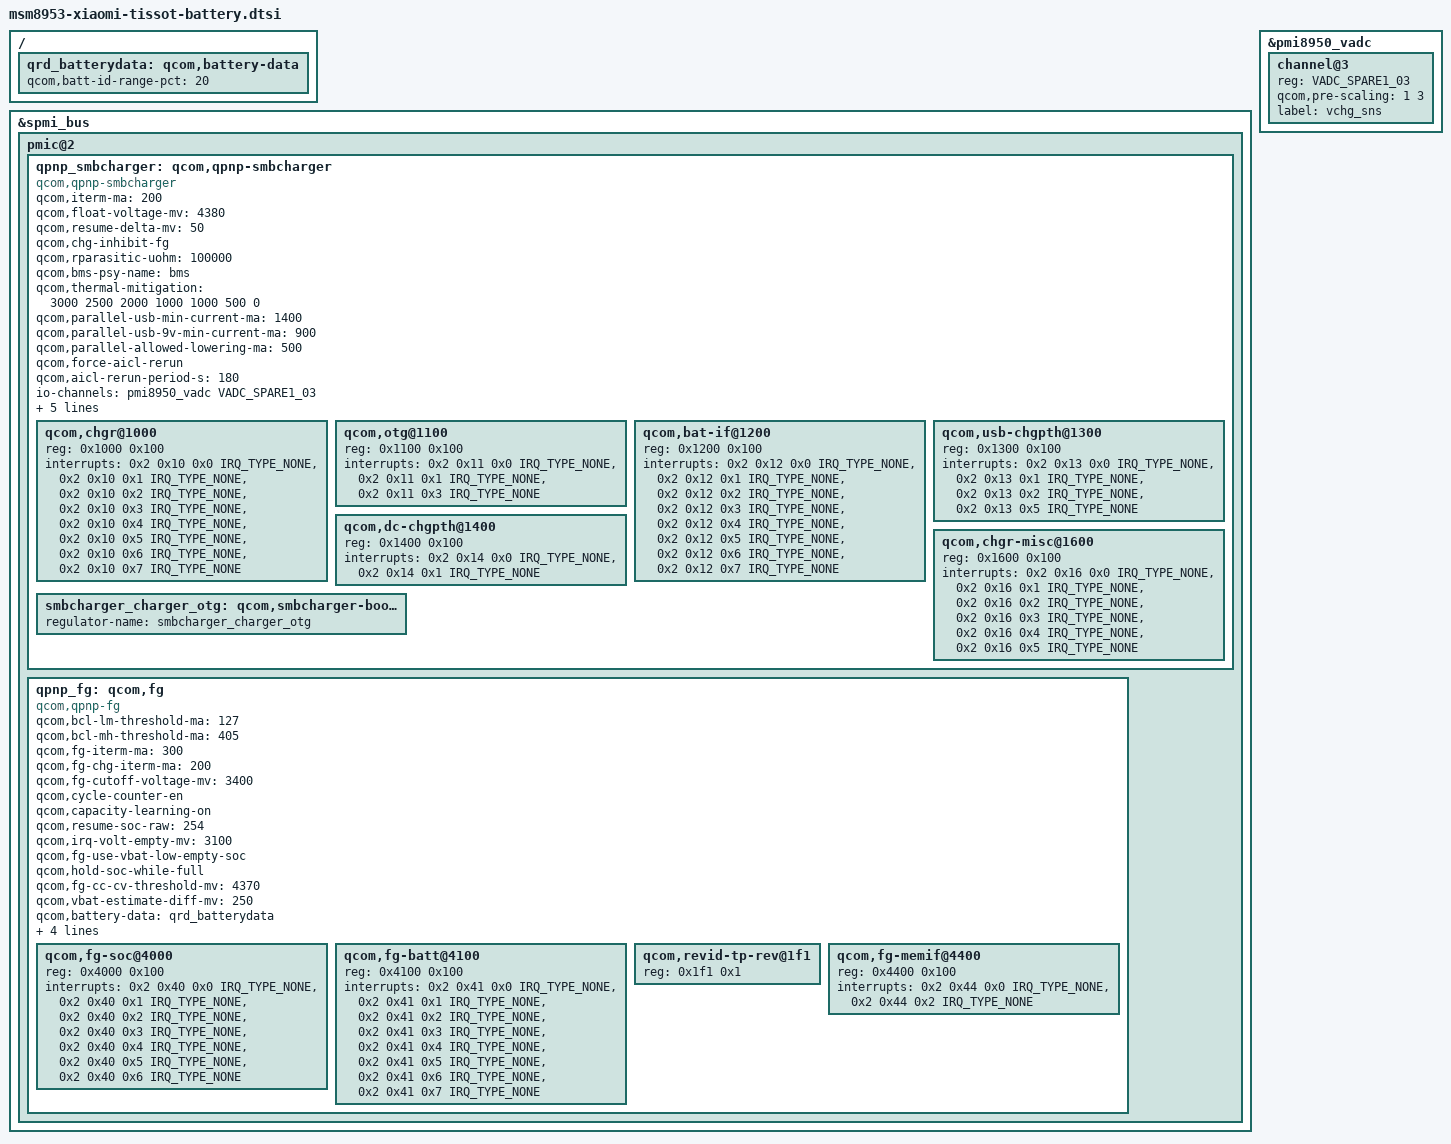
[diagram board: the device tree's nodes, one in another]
// SPDX-License-Identifier: GPL-2.0-only
/* PMI8950 peripheral layout and calibration from the oc-test Tissot donor. */

&spmi_bus {
	pmic@2 {
		qpnp_smbcharger: qcom,qpnp-smbcharger {
			compatible = "qcom,qpnp-smbcharger";
			#address-cells = <1>;
			#size-cells = <1>;
			#cooling-cells = <2>;

			qcom,iterm-ma = <100>;
			qcom,float-voltage-mv = <4200>;
			qcom,resume-delta-mv = <200>;
			qcom,chg-inhibit-fg;
			qcom,rparasitic-uohm = <100000>;
			qcom,bms-psy-name = "bms";
			qcom,thermal-mitigation = <1500 700 600 0>;
			qcom,parallel-usb-min-current-ma = <1400>;
			qcom,parallel-usb-9v-min-current-ma = <900>;
			qcom,parallel-allowed-lowering-ma = <500>;
			qcom,force-aicl-rerun;
			qcom,aicl-rerun-period-s = <180>;
			qcom,autoadjust-vfloat;

			io-channels = <&pmi8950_vadc VADC_SPARE1_03>;
			io-channel-names = "vchg_sns";

			qcom,chgr@1000 {
				reg = <0x1000 0x100>;
				interrupts =	<0x2 0x10 0x0 IRQ_TYPE_NONE>,
						<0x2 0x10 0x1 IRQ_TYPE_NONE>,
						<0x2 0x10 0x2 IRQ_TYPE_NONE>,
						<0x2 0x10 0x3 IRQ_TYPE_NONE>,
						<0x2 0x10 0x4 IRQ_TYPE_NONE>,
						<0x2 0x10 0x5 IRQ_TYPE_NONE>,
						<0x2 0x10 0x6 IRQ_TYPE_NONE>,
						<0x2 0x10 0x7 IRQ_TYPE_NONE>;

				interrupt-names =	"chg-error",
							"chg-inhibit",
							"chg-prechg-sft",
							"chg-complete-chg-sft",
							"chg-p2f-thr",
							"chg-rechg-thr",
							"chg-taper-thr",
							"chg-tcc-thr";
			};

			qcom,otg@1100 {
				reg = <0x1100 0x100>;
				interrupts =	<0x2 0x11 0x0 IRQ_TYPE_NONE>,
						<0x2 0x11 0x1 IRQ_TYPE_NONE>,
						<0x2 0x11 0x3 IRQ_TYPE_NONE>;
				interrupt-names =	"otg-fail",
							"otg-oc",
						"usbid-change";
			};

			qcom,bat-if@1200 {
				reg = <0x1200 0x100>;
				interrupts =	<0x2 0x12 0x0 IRQ_TYPE_NONE>,
						<0x2 0x12 0x1 IRQ_TYPE_NONE>,
						<0x2 0x12 0x2 IRQ_TYPE_NONE>,
						<0x2 0x12 0x3 IRQ_TYPE_NONE>,
						<0x2 0x12 0x4 IRQ_TYPE_NONE>,
						<0x2 0x12 0x5 IRQ_TYPE_NONE>,
						<0x2 0x12 0x6 IRQ_TYPE_NONE>,
						<0x2 0x12 0x7 IRQ_TYPE_NONE>;

				interrupt-names =	"batt-hot",
							"batt-warm",
							"batt-cold",
							"batt-cool",
						"batt-ov",
							"batt-low",
							"batt-missing",
							"batt-term-missing";
			};

			qcom,usb-chgpth@1300 {
				reg = <0x1300 0x100>;
				interrupts =	<0x2 0x13 0x0 IRQ_TYPE_NONE>,
						<0x2 0x13 0x1 IRQ_TYPE_NONE>,
						<0x2 0x13 0x2 IRQ_TYPE_NONE>,
						<0x2 0x13 0x5 IRQ_TYPE_NONE>;

				interrupt-names =	"usbin-uv",
						"usbin-ov",
							"usbin-src-det",
							"aicl-done";
			};

			qcom,dc-chgpth@1400 {
				reg = <0x1400 0x100>;
				interrupts =	<0x2 0x14 0x0 IRQ_TYPE_NONE>,
						<0x2 0x14 0x1 IRQ_TYPE_NONE>;
				interrupt-names =	"dcin-uv",
							"dcin-ov";
			};

			qcom,chgr-misc@1600 {
				reg = <0x1600 0x100>;
				interrupts =	<0x2 0x16 0x0 IRQ_TYPE_NONE>,
						<0x2 0x16 0x1 IRQ_TYPE_NONE>,
						<0x2 0x16 0x2 IRQ_TYPE_NONE>,
						<0x2 0x16 0x3 IRQ_TYPE_NONE>,
						<0x2 0x16 0x4 IRQ_TYPE_NONE>,
						<0x2 0x16 0x5 IRQ_TYPE_NONE>;

				interrupt-names =	"power-ok",
							"temp-shutdown",
							"wdog-timeout",
							"flash-fail",
							"otst2",
							"otst3";
			};

			smbcharger_charger_otg: qcom,smbcharger-boost-otg {
				regulator-name = "smbcharger_charger_otg";
			};
		};

		qpnp_fg: qcom,fg {
			compatible = "qcom,qpnp-fg";
			#address-cells = <1>;
			#size-cells = <1>;
			qcom,resume-soc = <95>;
			status = "okay";
			qcom,bcl-lm-threshold-ma = <127>;
			qcom,bcl-mh-threshold-ma = <405>;
			qcom,fg-iterm-ma = <150>;
			qcom,fg-chg-iterm-ma = <100>;
			qcom,fg-cutoff-voltage-mv = <3500>;
			qcom,cycle-counter-en;
			qcom,capacity-learning-on;

			qcom,fg-soc@4000 {
			status = "okay";
				reg = <0x4000 0x100>;
				interrupts =	<0x2 0x40 0x0 IRQ_TYPE_NONE>,
						<0x2 0x40 0x1 IRQ_TYPE_NONE>,
						<0x2 0x40 0x2 IRQ_TYPE_NONE>,
						<0x2 0x40 0x3 IRQ_TYPE_NONE>,
						<0x2 0x40 0x4 IRQ_TYPE_NONE>,
						<0x2 0x40 0x5 IRQ_TYPE_NONE>,
						<0x2 0x40 0x6 IRQ_TYPE_NONE>;

				interrupt-names =	"high-soc",
							"low-soc",
							"full-soc",
							"empty-soc",
							"delta-soc",
							"first-est-done",
							"update-soc";
			};

			qcom,fg-batt@4100 {
				reg = <0x4100 0x100>;
				interrupts =	<0x2 0x41 0x0 IRQ_TYPE_NONE>,
						<0x2 0x41 0x1 IRQ_TYPE_NONE>,
						<0x2 0x41 0x2 IRQ_TYPE_NONE>,
						<0x2 0x41 0x3 IRQ_TYPE_NONE>,
						<0x2 0x41 0x4 IRQ_TYPE_NONE>,
						<0x2 0x41 0x5 IRQ_TYPE_NONE>,
						<0x2 0x41 0x6 IRQ_TYPE_NONE>,
						<0x2 0x41 0x7 IRQ_TYPE_NONE>;

				interrupt-names =	"soft-cold",
							"soft-hot",
							"vbatt-low",
							"batt-ided",
							"batt-id-req",
							"batt-unknown",
							"batt-missing",
							"batt-match";
			};

			qcom,revid-tp-rev@1f1 {
				reg = <0x1f1 0x1>;
			};

			qcom,fg-memif@4400 {
				status = "okay";
				reg = <0x4400 0x100>;
				interrupts =	<0x2 0x44 0x0 IRQ_TYPE_NONE>,
						<0x2 0x44 0x2 IRQ_TYPE_NONE>;

				interrupt-names =	"mem-avail",
							"data-rcvry-sug";
			};
		};
	};
};

/ {
	qrd_batterydata: qcom,battery-data {
		qcom,batt-id-range-pct = <20>;
		#include "batterydata-qrd-coslight-3000mAh.dtsi"
		#include "batterydata-qrd-scud-3000mAh.dtsi"
		#include "batterydata-qrd-sunwoda-liwei-3000mAh.dtsi"
	};
};

&qpnp_smbcharger {
	compatible = "qcom,qpnp-smbcharger";

    qcom,iterm-ma = <200>;
	qcom,float-voltage-mv = <4380>;
	qcom,resume-delta-mv = <50>;
	qcom,charge-unknown-battery;
	/delete-property/ qcom,autoadjust-vfloat;
	qcom,override-usb-current;
	qcom,fastchg-current-comp = <900>;
	qcom,float-voltage-comp = <15>;
    qcom,battery-data = <&qrd_batterydata>;
    /delete-property/ qcom,chg-led-sw-controls;
	/delete-property/ qcom,chg-led-support;
	/delete-property/ qcom,external-typec;
	/delete-property/ qcom,typec-psy-name;
	qcom,thermal-mitigation = <3000 2500 2000 1000 1000 500 0>;
    io-channels = <&pmi8950_vadc VADC_SPARE1_03>;
	io-channel-names = "vchg_sns";
    status = "okay";
};

&qpnp_fg {
	compatible = "qcom,qpnp-fg";

    /delete-property/ qcom,resume-soc;
	qcom,resume-soc-raw = <254>;
	qcom,fg-iterm-ma = <300>;
	qcom,fg-chg-iterm-ma = <200>;
	qcom,fg-cutoff-voltage-mv = <3400>;
	qcom,irq-volt-empty-mv = <3100>;
	qcom,fg-use-vbat-low-empty-soc;
	qcom,hold-soc-while-full;
	qcom,fg-cc-cv-threshold-mv = <4370>;
	qcom,vbat-estimate-diff-mv = <250>;
    qcom,battery-data = <&qrd_batterydata>;
    qcom,thermal-coefficients = [c8 86 c1 50 d3 37];
	qcom,cold-bat-decidegc = <0>;
	qcom,cool-bat-decidegc = <150>;
	qcom,warm-bat-decidegc = <450>;
    status = "okay";
};

&pmi8950_vadc {
	/* The donor's VCHG_SNS_LEGACY is hardware channel 3, not channel 2. */
	channel@3 {
		reg = <VADC_SPARE1_03>;
		qcom,pre-scaling = <1 3>;
		label = "vchg_sns";
	};
};
